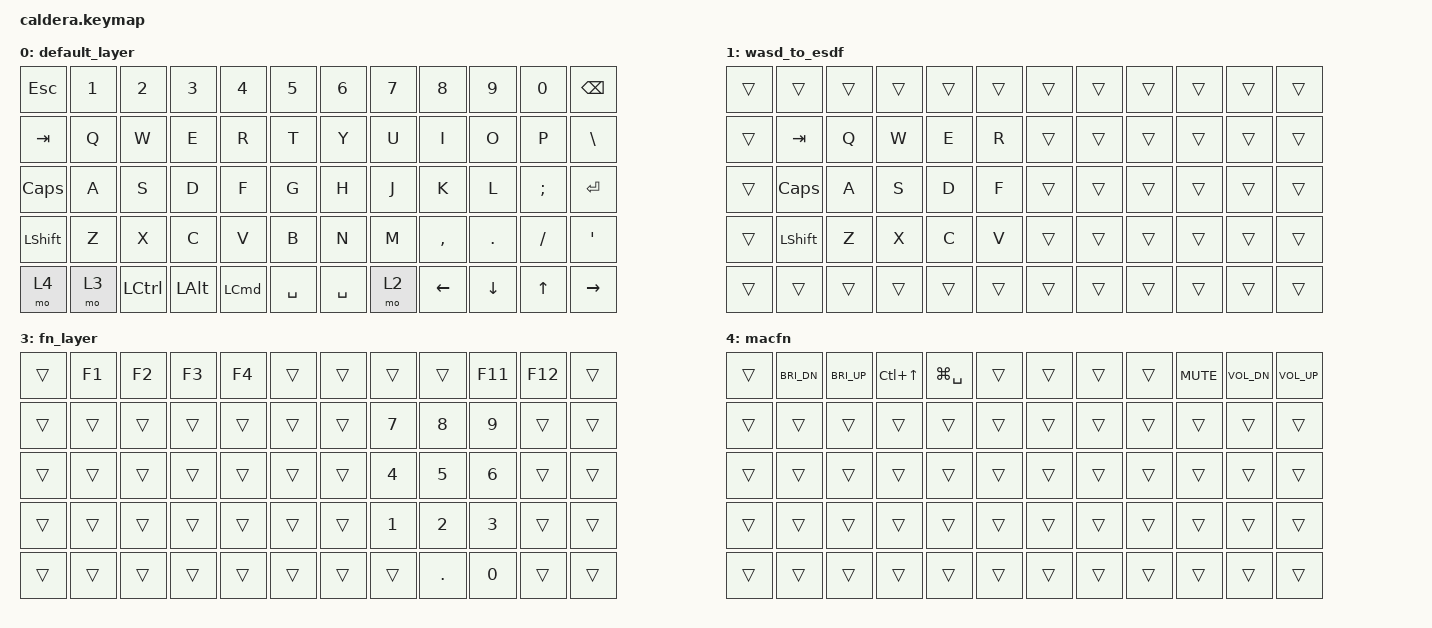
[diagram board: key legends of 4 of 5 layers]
#include <behaviors.dtsi>
#include <dt-bindings/zmk/bt.h>
#include <dt-bindings/zmk/keys.h>

/ {
    combos {
        compatible = "zmk,combos";

        combo_esdf {
            bindings = <&tog 1>;
            key-positions = <0 48 53>;
        };
    };

    keymap {
        compatible = "zmk,keymap";

        default_layer {
            // ---------------------------------------------------------------------------------
            // |   `  |  1  |  2  |  3  |  4  |  5  |     |  6  |  7  |  8  |  9  |  0  | BKSP |
            // |  TAB |  Q  |  W  |  E  |  R  |  T  |     |  Y  |  U  |  I  |  O  |  P  |  \   |
            // | CAPS |  A  |  S  |  D  |  F  |  G  |     |  H  |  J  |  K  |  L  |  ;  |  ENT |
            // | SHFT |  Z  |  X  |  C  |  V  |  B  |     |  N  |  M  |  ,  |  .  |  /  | APOS |
            // | CTRL | ALT | GUI | SPC | SPC | SPC |     | SPC | LOW |LARW |DARW |UARW | RARW |

            bindings = <
&kp ESC    &kp N1  &kp N2     &kp N3        &kp N4            &kp N5       &kp N6     &kp N7  &kp N8     &kp N9    &kp N0    &kp BSPC
&kp TAB    &kp Q   &kp W      &kp E         &kp R             &kp T        &kp Y      &kp U   &kp I      &kp O     &kp P     &kp BSLH
&kp CAPS   &kp A   &kp S      &kp D         &kp F             &kp G        &kp H      &kp J   &kp K      &kp L     &kp SEMI  &kp RET
&kp LSHFT  &kp Z   &kp X      &kp C         &kp V             &kp B        &kp N      &kp M   &kp COMMA  &kp DOT   &kp FSLH  &kp APOS
&mo 4      &mo 3   &kp LCTRL  &kp LEFT_ALT  &kp LEFT_COMMAND  &kp SPACE    &kp SPACE  &mo 2   &kp LEFT   &kp DOWN  &kp UP    &kp RIGHT
            >;
        };

        wasd_to_esdf {
            bindings = <
&trans  &trans     &trans  &trans  &trans  &trans    &trans  &trans  &trans  &trans  &trans  &trans
&trans  &kp TAB    &kp Q   &kp W   &kp E   &kp R     &trans  &trans  &trans  &trans  &trans  &trans
&trans  &kp CAPS   &kp A   &kp S   &kp D   &kp F     &trans  &trans  &trans  &trans  &trans  &trans
&trans  &kp LSHFT  &kp Z   &kp X   &kp C   &kp V     &trans  &trans  &trans  &trans  &trans  &trans
&trans  &trans     &trans  &trans  &trans  &trans    &trans  &trans  &trans  &trans  &trans  &trans
            >;
        };

        lower_layer {
            // ------------------------------------------------------------------------------------------------------------
            // |       |  BT1  |  BT2  |  BT3  |  BT4  |  BT5  |          |       |       |       |       |       | BTCLR |
            // |       |       |       |       |       |       |          |       |       |       |       |       |       |
            // |       |       |       | LPAR  | RPAR  |       |          |       | LBKT  | RBKT  |       |       |       |
            // |       |       |       |       |       |       |          |       |       |       |       |       |       |

            bindings = <
&trans      &bt BT_SEL 0  &bt BT_SEL 1  &bt BT_SEL 2  &bt BT_SEL 3  &bt BT_SEL 4    &trans  &trans          &trans           &trans     &trans     &trans
&trans      &trans        &trans        &trans        &trans        &trans          &trans  &kp LEFT_BRACE  &kp RIGHT_BRACE  &kp UNDER  &kp PLUS   &trans
&trans      &trans        &trans        &kp LPAR      &kp RPAR      &trans          &trans  &kp LBKT        &kp RBKT         &kp MINUS  &kp EQUAL  &trans
&bt BT_CLR  &trans        &trans        &trans        &trans        &trans          &trans  &trans          &trans           &trans     &trans     &trans
            >;
        };

        fn_layer {
            bindings = <
&trans  &kp F1  &kp F2  &kp F3  &kp F4  &trans    &trans  &trans  &trans   &kp F11  &kp F12  &trans
&trans  &trans  &trans  &trans  &trans  &trans    &trans  &kp N7  &kp N8   &kp N9   &trans   &trans
&trans  &trans  &trans  &trans  &trans  &trans    &trans  &kp N4  &kp N5   &kp N6   &trans   &trans
&trans  &trans  &trans  &trans  &trans  &trans    &trans  &kp N1  &kp N2   &kp N3   &trans   &trans
&trans  &trans  &trans  &trans  &trans  &trans    &trans  &trans  &kp DOT  &kp N0   &trans   &trans
            >;
        };

        macfn {
            bindings = <
&trans  &kp C_BRI_DN  &kp C_BRI_UP  &kp LC(UP_ARROW)  &kp LG(SPACE)  &trans    &trans  &trans  &trans  &kp C_MUTE  &kp C_VOL_DN  &kp C_VOL_UP
&trans  &trans        &trans        &trans            &trans         &trans    &trans  &trans  &trans  &trans      &trans        &trans
&trans  &trans        &trans        &trans            &trans         &trans    &trans  &trans  &trans  &trans      &trans        &trans
&trans  &trans        &trans        &trans            &trans         &trans    &trans  &trans  &trans  &trans      &trans        &trans
&trans  &trans        &trans        &trans            &trans         &trans    &trans  &trans  &trans  &trans      &trans        &trans
            >;
        };
    };
};
